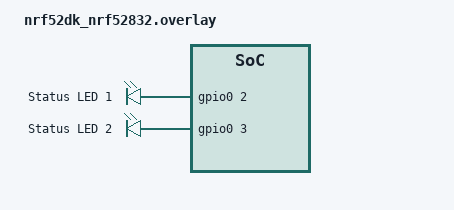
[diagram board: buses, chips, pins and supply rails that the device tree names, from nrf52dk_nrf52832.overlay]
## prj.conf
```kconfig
# 基础蓝牙
CONFIG_BT=y
CONFIG_BT_PERIPHERAL=y
CONFIG_BT_DEVICE_NAME="My_GATT_Demo"
CONFIG_BT_DEVICE_NAME_DYNAMIC=y
CONFIG_BT_DEVICE_NAME_MAX=65

CONFIG_BT_PHY_UPDATE=y
CONFIG_BT_USER_PHY_UPDATE=y

# 日志
CONFIG_LOG=y
CONFIG_USE_SEGGER_RTT=y
CONFIG_RTT_CONSOLE=y
CONFIG_LOG_BACKEND_RTT=y

# 栈空间
CONFIG_MAIN_STACK_SIZE=2048
CONFIG_SYSTEM_WORKQUEUE_STACK_SIZE=2048
```

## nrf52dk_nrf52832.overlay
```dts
/*
 * 这是一个设备树 Overlay 文件
 * 用于覆盖开发板默认的硬件定义
 */

/ {
    /* 定义我们自己的 LED 节点 */
    my_leds {
        compatible = "gpio-leds";
        
        /* 
         * LED 1 (对应 Day 1 的 P0.02)
         * &gpio0: 指的是 nRF52 的 Port 0
         * 2: 指的是 Pin 2
         * GPIO_ACTIVE_HIGH: 指的是高电平点亮 (1=亮, 0=灭)
         */
        led_custom_1: led_1 {
            gpios = <&gpio0 2 GPIO_ACTIVE_HIGH>;
            label = "Status LED 1";
        };

        /* LED 2 (对应 Day 1 的 P0.03) */
        led_custom_2: led_2 {
            gpios = <&gpio0 3 GPIO_ACTIVE_HIGH>;
            label = "Status LED 2";
        };
    };

    /* 
     * 修改别名 (Aliases)
     * 这样我们在 C 代码中调用 "led0" 时，
     * 实际上操作的是上面的 "led_custom_1" (P0.02)
     */
    aliases {
        led0 = &led_custom_1; /* 系统默认的 led0 现在指向 P0.02 */
        led1 = &led_custom_2; /* 系统默认的 led1 现在指向 P0.03 */
    };
};
```

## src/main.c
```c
#include <zephyr/types.h>
#include <stddef.h>
#include <zephyr/sys/printk.h>
#include <zephyr/sys/util.h>
#include <zephyr/bluetooth/bluetooth.h>
#include <zephyr/bluetooth/hci.h>
#include <zephyr/bluetooth/conn.h>
#include <zephyr/bluetooth/uuid.h>
#include <zephyr/bluetooth/gatt.h>
#include <zephyr/logging/log.h>

// 引入我们刚才写的服务头文件
#include "my_service.h"

LOG_MODULE_REGISTER(main, LOG_LEVEL_INF);

// --- 广播数据配置 ---

/* 
 * ad (Advertising Data): 广播包数据，最大 31 字节。
 * 这里我们放入了两个重要元素：
 * 1. Flags: 说明设备模式（如：有限发现/一般发现，不支持经典蓝牙）。
 * 2. UUID: 将我们的 128-bit 自定义服务 UUID 放入广播包。
 *    注意：128-bit UUID 占 16 字节，加上类型头，非常占空间。
 */
static const struct bt_data ad[] = {
    // 设置广播 Flags
    // BT_LE_AD_GENERAL: 一般可发现模式 (手机可以一直扫描到)
    // BT_LE_AD_NO_BREDR: 不支持经典蓝牙 (仅 BLE)
    BT_DATA_BYTES(BT_DATA_FLAGS, (BT_LE_AD_GENERAL | BT_LE_AD_NO_BREDR)),

    /* 
     * API 解析: BT_DATA_BYTES
     * 功能: 将一串字节序列构造成符合 BLE 格式的广播数据结构 (struct bt_data)。
     * 参数1: 数据类型 (Data Type)。
     *        BT_DATA_UUID128_ALL 表示“完整的 128-bit 服务 UUID 列表”。
     *        这意味着设备只支持这一个服务，或者列表里包含了所有支持的服务。
     * 参数2: 具体的 UUID 值 (来自 my_service.h 中的宏)。
     */
    BT_DATA_BYTES(BT_DATA_UUID128_ALL, MY_SERVICE_UUID_VAL),
};

/* 
 * sd (Scan Response Data): 扫描响应数据。
 * 当手机主动发起“扫描请求”时，设备回复的数据。
 * 通常把“设备名称”放在这里，以节省广播包 (ad) 的空间。
 */
static const struct bt_data sd[] = {
    // 将设备名称放入扫描响应包中
    BT_DATA(BT_DATA_NAME_COMPLETE, CONFIG_BT_DEVICE_NAME, sizeof(CONFIG_BT_DEVICE_NAME) - 1),
};

// --- 系统初始化与主循环 ---

void main(void)
{
    int err;

    LOG_INF("Starting Bluetooth Peripheral GATT Demo");

    // 1. 初始化蓝牙协议栈
    // API: bt_enable(callback)
    // 功能: 初始化控制器和主机协议栈。如果传入 NULL，则同步初始化，成功返回 0。
    err = bt_enable(NULL);
    if (err) {
        LOG_ERR("Bluetooth init failed (err %d)", err);
        return;
    }
    LOG_INF("Bluetooth initialized");

    // 2. 初始化我们的自定义服务
    // 虽然 BT_GATT_SERVICE_DEFINE 是静态宏，但如果有动态逻辑可以在这里调用 init
    my_service_init();

    // 3. 开始广播
    // API: bt_le_adv_start(param, ad, ad_len, sd, sd_len)
    // 参数1: 广播参数 (BT_LE_ADV_CONN_NAME 表示可连接广播，并尝试在广播包中包含名字)
    //        *注：因为我们手动定义了 ad 和 sd，这里用 BT_LE_ADV_CONN 即可
    // 参数2/3: 广播数据数组及其大小
    // 参数4/5: 扫描响应数据数组及其大小
    err = bt_le_adv_start(BT_LE_ADV_CONN, ad, ARRAY_SIZE(ad), sd, ARRAY_SIZE(sd));
    if (err) {
        LOG_ERR("Advertising failed to start (err %d)", err);
        return;
    }

    LOG_INF("Advertising successfully started...");
    LOG_INF("Waiting for connection...");

    // 主线程可以休眠了，所有的逻辑现在都由 BLE 协议栈线程和回调函数驱动
    while (1) {
        k_sleep(K_FOREVER);
    }
}
```

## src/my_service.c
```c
#include "my_service.h"
#include <zephyr/logging/log.h>

// 注册日志模块，名称为 "my_srv"
LOG_MODULE_REGISTER(my_srv, LOG_LEVEL_INF);

// 1. 定义特征值的数据缓冲区 (例如 64 字节)
static uint8_t my_value[64] = {0x11, 0x22, 0x33, 0x44}; // 给个初始值，方便 Read 测试

// 2. 实现 Write 回调函数
// 当手机向 Characteristic 写入数据时，协议栈会调用此函数
static ssize_t on_write(struct bt_conn *conn,
                        const struct bt_gatt_attr *attr,
                        const void *buf,
                        uint16_t len,
                        uint16_t offset,
                        uint8_t flags)
{
    // attr->user_data 指向的是我们在定义服务时绑定的变量 (即 my_value)
    uint8_t *value = attr->user_data;

    // 检查写入长度是否越界
    if (offset + len > sizeof(my_value)) {
        return BT_GATT_ERR(BT_ATT_ERR_INVALID_OFFSET);
    }

    // 将数据复制到我们的缓冲区
    memcpy(value + offset, buf, len);

    // 打印接收到的数据 (Hex 格式)
    LOG_INF("Data written: len=%d, data=", len);
    LOG_HEXDUMP_INF(buf, len, "Payload");

    // 返回实际写入的长度
    return len;
}

// 自定义 Read 回调
// 自定义 Read 回调
static ssize_t on_read(struct bt_conn *conn,
                       const struct bt_gatt_attr *attr,
                       void *buf,
                       uint16_t len,
                       uint16_t offset)
{
    const uint8_t *value = attr->user_data;

    LOG_INF("Read request received");

    // 这里必须调用 bt_gatt_attr_read (带 attr 字样)
    // 它的作用是帮你处理 buf 的边界检查、offset 偏移和数据复制
    return bt_gatt_attr_read(conn, attr, buf, len, offset, value, sizeof(my_value));
}
// 3. 定义 GATT 服务
// 这是一个宏，会在编译时静态创建一个 GATT 服务结构体
BT_GATT_SERVICE_DEFINE(my_service,
    // (1) 服务声明：主服务 (Primary Service)
    BT_GATT_PRIMARY_SERVICE(MY_SERVICE_UUID),

    // (2) 特征值定义
    // 参数1: 特征值的 UUID
    // 参数2: 属性 (Properties) - 告诉手机这个特征支持 Read 和 Write
    // 参数3: 权限 (Permissions) - 告诉协议栈，读写是否需要加密/认证 (这里设为 Open，即无需加密)
    // 参数4: Read 回调函数 - 使用系统默认的 bt_gatt_attr_read，它会直接读取 user_data
    // 参数5: Write 回调函数 - 使用我们自定义的 on_write
    // 参数6: user_data - 绑定的数据缓冲区
    BT_GATT_CHARACTERISTIC(MY_CHAR_UUID,
                           BT_GATT_CHRC_READ | BT_GATT_CHRC_WRITE,
                           BT_GATT_PERM_READ | BT_GATT_PERM_WRITE,
                           on_read, on_write, my_value),
);

// 初始化函数 (目前 GATT 是静态定义的，这个函数可以留空，或者做一些额外逻辑)
int my_service_init(void)
{
    return 0;
}
```

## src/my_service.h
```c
#ifndef MY_SERVICE_H_
#define MY_SERVICE_H_

#include <zephyr/types.h>
#include <stddef.h>
#include <zephyr/bluetooth/conn.h>
#include <zephyr/bluetooth/uuid.h>
#include <zephyr/bluetooth/gatt.h>

/**
 * @brief 自定义服务 UUID
 * UUID String: d5a6e878-df0c-442d-83b6-200384e51921
 */
#define MY_SERVICE_UUID_VAL \
	BT_UUID_128_ENCODE(0xd5a6e878, 0xdf0c, 0x442d, 0x83b6, 0x200384e51921)

/**
 * @brief 自定义特征值 UUID (Read/Write)
 * UUID String: d5a6e879-df0c-442d-83b6-200384e51921
 * 注意：通常我们会让 Characteristic 的 UUID 与 Service 只差 1 个 bit 或 byte，方便辨识
 */
#define MY_CHAR_UUID_VAL \
	BT_UUID_128_ENCODE(0xd5a6e879, 0xdf0c, 0x442d, 0x83b6, 0x200384e51921)

// 将宏封装成 Zephyr 的 UUID 结构体指针，方便后续调用
#define MY_SERVICE_UUID BT_UUID_DECLARE_128(MY_SERVICE_UUID_VAL)
#define MY_CHAR_UUID    BT_UUID_DECLARE_128(MY_CHAR_UUID_VAL)

/**
 * @brief 初始化服务的函数声明
 * 我们将在 main.c 中调用它
 */
int my_service_init(void);

#endif /* MY_SERVICE_H_ */
```
